VERSION ""

NS_ :

BS_:

BU_:

BO_ 257 set_servo: 8 Vector__XXX
 SG_ set_servo_position : 23|1@0+ (1,0) [0|0] "boolean" Vector__XXX
 SG_ servo_position : 7|12@0+ (1,0) [0|0] "microseconds" Vector__XXX

BO_ 272 status: 8 Vector__XXX
 SG_ over_rev : 7|1@0+ (1,0) [0|0] "boolean" Vector__XXX
 SG_ antistall : 6|1@0+ (1,0) [0|0] "boolean" Vector__XXX

BO_ 256 servo: 8 Vector__XXX
 SG_ servo_percentage : 23|16@0+ (1,0) [0|0] "%" Vector__XXX
 SG_ servo_position : 7|12@0+ (1,0) [0|0] "microseconds" Vector__XXX

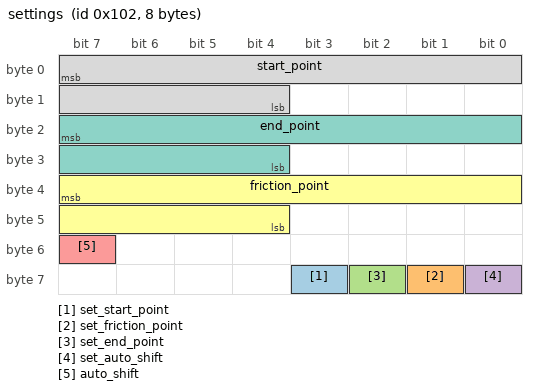
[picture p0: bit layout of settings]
BO_ 258 settings: 8 Vector__XXX
 SG_ set_start_point : 59|1@0+ (1,0) [0|0] "boolean" Vector__XXX
 SG_ set_friction_point : 57|1@0+ (1,0) [0|0] "boolean" Vector__XXX
 SG_ set_end_point : 58|1@0+ (1,0) [0|0] "boolean" Vector__XXX
 SG_ set_auto_shift : 56|1@0+ (1,0) [0|0] "boolean" Vector__XXX
 SG_ auto_shift : 55|1@0+ (1,0) [0|0] "boolean" Vector__XXX
 SG_ friction_point : 39|12@0+ (1,0) [0|0] "microseconds" Vector__XXX
 SG_ end_point : 23|12@0+ (1,0) [0|0] "microseconds" Vector__XXX
 SG_ start_point : 7|12@0+ (1,0) [0|0] "microseconds" Vector__XXX

BA_DEF_  "BusType" STRING ;
BA_DEF_DEF_  "BusType" "CAN";
